AUTOSAR XML (schema 00044)
package /VehicleProject
  system System
    system mapping BMW_MPPNG
      data-mappings:
        sender-receiver-to-signal-mapping={data-element=Ambient_Light_level, system-signal=Ambient_Light_level}
        sender-receiver-to-signal-mapping={data-element=DayNightMode, system-signal=DayNightMode}
        sender-receiver-to-signal-mapping={data-element=Gear, system-signal=Gear}
        sender-receiver-to-signal-mapping={data-element=GearMode, system-signal=GearMode}
        sender-receiver-to-signal-mapping={data-element=GearRecommendation, system-signal=GearRecommendation}
        sender-receiver-to-signal-mapping={data-element=GearStatus, system-signal=GearStatus}
        sender-receiver-to-signal-mapping={data-element=Illumination_level, system-signal=Illumination_level}
        sender-receiver-to-signal-mapping={data-element=PowerMode, system-signal=PowerMode}
        sender-receiver-to-signal-mapping={data-element=TransportMode, system-signal=TransportMode}
        sender-receiver-to-signal-mapping={data-element=Warning, system-signal=Warning}
        sender-receiver-to-signal-mapping={data-element=Battery_Voltage, system-signal=Battery_Voltage}
        sender-receiver-to-signal-mapping={data-element=Debug1_Byte{0..7}, system-signal=Debug1_Byte{0..7}}
        sender-receiver-to-signal-mapping={data-element=Debug2_Byte{0..7}, system-signal=Debug2_Byte{0..7}}
        sender-receiver-to-signal-mapping={data-element=Debug3_Byte{0..7}, system-signal=Debug3_Byte{0..7}}
        sender-receiver-to-signal-mapping={data-element=Debug4_Byte{0..7}, system-signal=Debug4_Byte{0..7}}
        sender-receiver-to-signal-mapping={data-element=Debug5_Byte{0..7}, system-signal=Debug5_Byte{0..7}}
        sender-receiver-to-signal-mapping={data-element=FV_Tx, system-signal=FV_Tx}
        sender-receiver-to-signal-mapping={data-element=Illumination_PWM, system-signal=Illumination_PWM}
        sender-receiver-to-signal-mapping={data-element=MAC_Tx, system-signal=MAC_Tx}
        sender-receiver-to-signal-mapping={data-element=Odometer, system-signal=Odometer}
        sender-receiver-to-signal-mapping={data-element=SecureTxByte{0..3}, system-signal=SecureTxByte{0..3}}
        sender-receiver-to-signal-mapping={data-element=VehicleSpeedIC, system-signal=VehicleSpeedIC}
        sender-receiver-to-signal-group-mapping={data-element=SG_COM_HS, signal-group=SG_COM_HS, type-mapping=sender-rec-record-type-mapping=record-element-mappings=[{implementation-record-element=Alive_200, system-signal=Alive_200}, {implementation-record-element=Battery_Voltage, system-signal=Battery_Voltage}, {implementation-record-element=CRC_200, system-signal=CRC_200}]}
        sender-receiver-to-signal-group-mapping={data-element=PP_TX_SG_COM_HSSG_COM_HS.SG_COM_HS, signal-group=SG_COM_HS, type-mapping=sender-rec-record-type-mapping=record-element-mappings=[{implementation-record-element=Alive_200, system-signal=Alive_200}, {implementation-record-element=Battery_Voltage, system-signal=Battery_Voltage}, {implementation-record-element=CRC_200, system-signal=CRC_200}]}
        sender-receiver-to-signal-mapping={data-element=rp_SR_RxAmbient_Light_level.Ambient_Light_level, system-signal=Ambient_Light_level}
        sender-receiver-to-signal-mapping={data-element=CurrentStateIC, system-signal=CurrentStateIC}
        sender-receiver-to-signal-mapping={data-element=rp_SR_RxDayNightMode.DayNightMode, system-signal=DayNightMode}
        sender-receiver-to-signal-mapping={data-element=rp_SR_RxGear.Gear, system-signal=Gear}
        sender-receiver-to-signal-mapping={data-element=rp_SR_RxGearMode.GearMode, system-signal=GearMode}
        sender-receiver-to-signal-mapping={data-element=rp_SR_RxGearRecommendation.GearRecommendation, system-signal=GearRecommendation}
        sender-receiver-to-signal-mapping={data-element=rp_SR_RxGearStatus.GearStatus, system-signal=GearStatus}
        sender-receiver-to-signal-mapping={data-element=rp_SR_RxIllumination_level.Illumination_level, system-signal=Illumination_level}
        sender-receiver-to-signal-mapping={data-element=rp_SR_RxPowerMode.PowerMode, system-signal=PowerMode}
        sender-receiver-to-signal-mapping={data-element=rp_SR_RxTransportMode.TransportMode, system-signal=TransportMode}
        sender-receiver-to-signal-mapping={data-element=rp_SR_RxWarning.Warning, system-signal=Warning}
        sender-receiver-to-signal-mapping={data-element=pp_SR_TxDebug1_Byte{0..7}.Debug1_Byte{0..7}, system-signal=Debug1_Byte{0..7}}
        sender-receiver-to-signal-mapping={data-element=pp_SR_TxDebug2_Byte{0..7}.Debug2_Byte{0..7}, system-signal=Debug2_Byte{0..7}}
        sender-receiver-to-signal-mapping={data-element=pp_SR_TxDebug3_Byte{0..7}.Debug3_Byte{0..7}, system-signal=Debug3_Byte{0..7}}
        sender-receiver-to-signal-mapping={data-element=pp_SR_TxDebug4_Byte{0..7}.Debug4_Byte{0..7}, system-signal=Debug4_Byte{0..7}}
        sender-receiver-to-signal-mapping={data-element=pp_SR_TxDebug5_Byte{0..7}.Debug5_Byte{0..7}, system-signal=Debug5_Byte{0..7}}
        sender-receiver-to-signal-mapping={data-element=pp_SR_TxFV_Tx.FV_Tx, system-signal=FV_Tx}
        sender-receiver-to-signal-mapping={data-element=pp_SR_TxIllumination_PWM.Illumination_PWM, system-signal=Illumination_PWM}
        sender-receiver-to-signal-mapping={data-element=pp_SR_TxMAC_Tx.MAC_Tx, system-signal=MAC_Tx}
        sender-receiver-to-signal-mapping={data-element=pp_SR_TxOdometer.Odometer, system-signal=Odometer}
        sender-receiver-to-signal-mapping={data-element=pp_SR_TxSecureTxByte{0..3}.SecureTxByte{0..3}, system-signal=SecureTxByte{0..3}}
        sender-receiver-to-signal-mapping={data-element=pp_SR_TxVehicleSpeedIC.VehicleSpeedIC, system-signal=VehicleSpeedIC}
        sender-receiver-to-signal-mapping={data-element=EngineSpeed, system-signal=EngineSpeed}
        sender-receiver-to-signal-mapping={data-element=Turn_Indicator_Control, system-signal=Turn_Indicator_Control}
        sender-receiver-to-signal-mapping={data-element=rp_SR_RxEngineSpeed.EngineSpeed, system-signal=EngineSpeed}
        sender-receiver-to-signal-mapping={data-element=rp_SR_RxTurn_Indicator_Control.Turn_Indicator_Control, system-signal=Turn_Indicator_Control}
    root-software-compositions:
      root sw composition prototype SoftwareArchitecture: software-composition=E40_Platform_System
package /E40_Platform_System_SystemPackage/Compositions
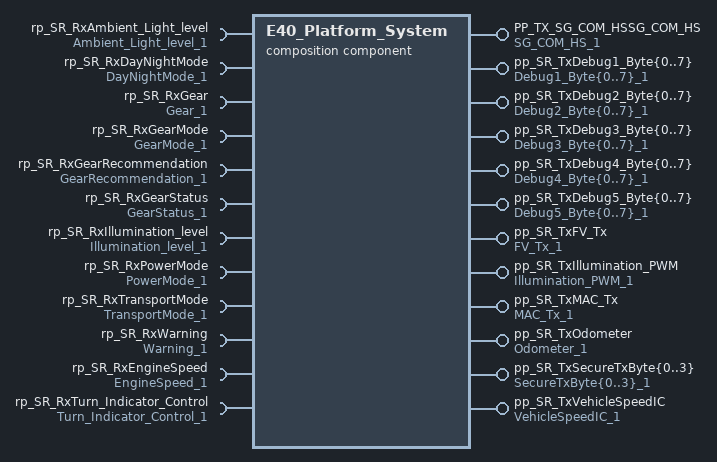
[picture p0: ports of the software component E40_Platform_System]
  composition sw component type E40_Platform_System
    provide port PP_TX_SG_COM_HSSG_COM_HS: nonqueued-sender-com-spec{data-element=SG_COM_HS, init-value=fields=[Alive_200:0, Battery_Voltage:0, CRC_200:0]}, provided-interface=SG_COM_HS_1
    10 x require port:
      rp_SR_RxAmbient_Light_level: nonqueued-receiver-com-spec{data-element=Ambient_Light_level, init-value=0}, required-interface=Ambient_Light_level_1
      rp_SR_RxDayNightMode: nonqueued-receiver-com-spec{data-element=DayNightMode, init-value=0}, required-interface=DayNightMode_1
      rp_SR_RxGear: nonqueued-receiver-com-spec{data-element=Gear, init-value=0}, required-interface=Gear_1
      rp_SR_RxGearMode: nonqueued-receiver-com-spec{data-element=GearMode, init-value=0}, required-interface=GearMode_1
      rp_SR_RxGearRecommendation: nonqueued-receiver-com-spec{data-element=GearRecommendation, init-value=0}, required-interface=GearRecommendation_1
      rp_SR_RxGearStatus: nonqueued-receiver-com-spec{data-element=GearStatus, init-value=0}, required-interface=GearStatus_1
      rp_SR_RxIllumination_level: nonqueued-receiver-com-spec{data-element=Illumination_level, init-value=0}, required-interface=Illumination_level_1
      rp_SR_RxPowerMode: nonqueued-receiver-com-spec{data-element=PowerMode, init-value=0}, required-interface=PowerMode_1
      rp_SR_RxTransportMode: nonqueued-receiver-com-spec{data-element=TransportMode, init-value=0}, required-interface=TransportMode_1
      rp_SR_RxWarning: nonqueued-receiver-com-spec{data-element=Warning, init-value=0}, required-interface=Warning_1
    49 x provide port:
      pp_SR_TxDebug1_Byte{0..7}: nonqueued-sender-com-spec{data-element=Debug1_Byte{0..7}, init-value=0}, provided-interface=Debug1_Byte{0..7}_1
      pp_SR_TxDebug2_Byte{0..7}: nonqueued-sender-com-spec{data-element=Debug2_Byte{0..7}, init-value=0}, provided-interface=Debug2_Byte{0..7}_1
      pp_SR_TxDebug3_Byte{0..7}: nonqueued-sender-com-spec{data-element=Debug3_Byte{0..7}, init-value=0}, provided-interface=Debug3_Byte{0..7}_1
      pp_SR_TxDebug4_Byte{0..7}: nonqueued-sender-com-spec{data-element=Debug4_Byte{0..7}, init-value=0}, provided-interface=Debug4_Byte{0..7}_1
      pp_SR_TxDebug5_Byte{0..7}: nonqueued-sender-com-spec{data-element=Debug5_Byte{0..7}, init-value=0}, provided-interface=Debug5_Byte{0..7}_1
      pp_SR_TxFV_Tx: nonqueued-sender-com-spec{data-element=FV_Tx, init-value=0}, provided-interface=FV_Tx_1
      pp_SR_TxIllumination_PWM: nonqueued-sender-com-spec{data-element=Illumination_PWM, init-value=0}, provided-interface=Illumination_PWM_1
      pp_SR_TxMAC_Tx: nonqueued-sender-com-spec{data-element=MAC_Tx, init-value=0}, provided-interface=MAC_Tx_1
      pp_SR_TxOdometer: nonqueued-sender-com-spec{data-element=Odometer, init-value=0}, provided-interface=Odometer_1
      pp_SR_TxSecureTxByte{0..3}: nonqueued-sender-com-spec{data-element=SecureTxByte{0..3}, init-value=0}, provided-interface=SecureTxByte{0..3}_1
      pp_SR_TxVehicleSpeedIC: nonqueued-sender-com-spec{data-element=VehicleSpeedIC, init-value=0}, provided-interface=VehicleSpeedIC_1
    require port rp_SR_RxEngineSpeed: nonqueued-receiver-com-spec{data-element=EngineSpeed, init-value=0}, required-interface=EngineSpeed_1
    require port rp_SR_RxTurn_Indicator_Control: nonqueued-receiver-com-spec{data-element=Turn_Indicator_Control, init-value=0}, required-interface=Turn_Indicator_Control_1
    74 x component:
      Test_Comp: type=Test_Comp
      NvMExt: type=NvMExt
      EcuMExt: type=EcuMExt
      TmExt: type=TmExt
      IoHwAb: type=IoHwAb
      EcuAppM: type=EcuAppM
      MemAbstractMdl: type=MemAbstractMdl
      DmnMgr: type=DmnMgr
      SciDrv: type=SciDrv
      UclProxyCdd: type=UclProxyCdd
      CCDD_EcuPowerM: type=CCDD_EcuPowerM
      Dlt: type=Dlt
      DltExt: type=DltExt
      CDisplayCdd: type=CDisplayCdd
      CBacklightCdd: type=CBacklightCdd
      RtcCdd: type=RtcCdd
      DcmExt: type=DcmExt
      DemExt: type=DemExt
      CMeetCdd: type=CMeetCdd
      GdtCdd: type=GdtCdd
      WdgM: type=WdgM
      DcmApp: type=DcmApp
      DemApp: type=DemApp
      SafeBsw: type=SafeBsw
      CPmicCdd: type=CPmicCdd
      CIoExp: type=CIoExp
      CComAbsCtrl: type=CComAbsCtrl
      CComAbsMdl: type=CComAbsMdl
      CCtrl_Telltale: type=CCtrl_Telltale
      Ctrl_Dim: type=Ctrl_Dim
      Ctrl_warning: type=Ctrl_warning
      Ctrl_WSS: type=Ctrl_WSS
      CView_Telltale: type=CView_Telltale
      CWarnMsg_Core_Observer: type=CWarnMsg_Core_Observer
      FastGaugeAdapter: type=FastGaugeAdapter
      Mdl_Airbag: type=Mdl_Airbag
      Mdl_Dim: type=Mdl_Dim
      Mdl_Gear: type=Mdl_Gear
      Mdl_Linear_Interpolation: type=Mdl_Linear_Interpolation
      Mdl_SafetyAdapter: type=Mdl_SafetyAdapter
      Mdl_Speed: type=Mdl_Speed
      Mdl_Tacho: type=Mdl_Tacho
      Mdl_TurnHazard: type=Mdl_TurnHazard
      Mdl_wFuelLidOpen: type=Mdl_wFuelLidOpen
      Mdl_wAirbag: type=Mdl_wAirbag
      View_Speed: type=View_Speed
      SlowGaugeAdapter: type=SlowGaugeAdapter
      WarnMsg_Core_TmrSupport: type=WarnMsg_Core_TmrSupport
      ComMExt: type=ComMExt
      CorTst: type=CorTst
      FlsTst: type=FlsTst
      NvMExtSf: type=NvMExtSf
      RamTst: type=RamTst
      SysTst: type=SysTst
      MemAbstractStub: type=MemAbstractStub
      NvBlockSwComponentType: type=NvBlockSwComponentType
      CUpdateCdd: type=CUpdateCdd
      SafeNvM: type=SafeNvM
      MemAbstract_Stub_Safe: type=MemAbstract_Stub_Safe
      ComCallout: type=ComCallout
      CFltM: type=CFltM
      CFltMExt: type=CFltMExt
      CCDD_BswFit: type=CCDD_BswFit
      CCDD_FitManager: type=CCDD_FitManager
      CCDD_McuFit: type=CCDD_McuFit
      Ctrl_Illumination: type=Ctrl_Illumination
      View_Illumination: type=View_Illumination
      CComAbsMdl_stubs: type=CComAbsMdl_stubs
      CComAbsMdlSafe: type=CComAbsMdlSafe
      TrustecSWC: type=TrustecSWC
      CRstM: type=CRstM
      CSigCdd: type=CSigCdd
      CSwcDispMonSf: type=CSwcDispMonSf
      CCDD_EcuBatteryM: type=CCDD_EcuBatteryM
    connect IoHwAb.ppIoHwAb_Din -> CCDD_EcuPowerM.rpIoHwAb_Din
    connect IoHwAb.ppIoHwAb_DOut -> CCDD_EcuPowerM.rpIoHwAb_DOut
    connect IoHwAb.ppIoHwAb_PWM -> CCDD_EcuPowerM.rpIoHwAb_PWM
    connect IoHwAb.ppIoHwAb_ADC -> CCDD_EcuPowerM.rpIoHwAb_ADC
    connect MemAbstractMdl.pp_CS_MemAbsGet -> DltExt.rp_CS_MemAbsGet
    connect MemAbstractMdl.pp_CS_MemAbsSet -> DltExt.rp_CS_MemAbsSet
    connect MemAbstractMdl.pp_CS_MemAbs_NvMWriteStatus -> DltExt.rp_CS_MemAbs_NvMWriteStatus
    connect DmnMgr.ppCS_UclSystemCallbacks -> UclProxyCdd.rCS_UclSystemCallbacks
    connect DmnMgr.pSR_HealthDumpGetHdr -> UclProxyCdd.rSR_HealthDumpGetHdr
    connect DmnMgr.pSR_HealthDumpGetData -> UclProxyCdd.rSR_HealthDumpGetData
    connect DmnMgr.pSR_PowerSystemStateReqChange -> UclProxyCdd.rSR_PowerSystemStateReqChange
    connect UclProxyCdd.pSR_HealthDomainFatalError -> DmnMgr.rSR_HealthDomainFatalError
    connect UclProxyCdd.pSR_HealthDomainHeartbeat -> DmnMgr.rSR_HealthDomainHeartbeat
    connect UclProxyCdd.pSR_HealthDumpData -> DmnMgr.rSR_HealthDumpData
    connect UclProxyCdd.pSR_HealthDumpHdrInfo -> DmnMgr.rSR_HealthDumpHdrInfo
    connect UclProxyCdd.pSR_PowerExtendShutdownTime -> DmnMgr.rSR_PowerExtendShutdownTime
    connect UclProxyCdd.pSR_PowerKeepSystemAwake -> DmnMgr.rSR_PowerKeepSystemAwake
    connect UclProxyCdd.pSR_PowerSystemState -> DmnMgr.rSR_PowerSystemState
    connect UclProxyCdd.ppCS_UclInitShutdown -> DmnMgr.rpCS_UclInitShutdown
    connect DmnMgr.ppSR_DmnInfo -> DmnMgr.rpSR_DmnInfo
    connect DmnMgr.pp_CmpLibCmd_CDmnMgr -> EcuAppM.rp_CmpLibCmd_rp_CmpLibCmd_CDmnMgr
    connect UclProxyCdd.pp_CmpLibCmd_CUclProxyCdd -> EcuAppM.rp_CmpLibCmd_rp_CmpLibCmd_CUclProxyCdd
    connect EcuAppM.ppCS_EcuAppM -> EcuMExt.rpCS_EcuAppM
    connect NvBlockSwComponentType.BsShare_VisMeet_Element -> MemAbstractStub
    connect NvBlockSwComponentType.BsDiag_Dtc_Element -> MemAbstractStub
    connect NvBlockSwComponentType.BsRt_OilGauge_Element -> MemAbstractStub
    connect NvBlockSwComponentType.BsConst_ServiceReminder_Element -> MemAbstractStub
    connect NvBlockSwComponentType.BsRt_TachoGauge_Element -> MemAbstractStub
    connect NvBlockSwComponentType.BsConst_EngOffTimer_Element -> MemAbstractStub
    connect NvBlockSwComponentType.BsShare_ProductSerialNumber -> MemAbstractStub
    connect NvBlockSwComponentType.BsConst_OilGauge_Element -> MemAbstractStub
    connect NvBlockSwComponentType.BsRt_Odometer_Element -> MemAbstractStub
    connect NvBlockSwComponentType -> MemAbstractStub
    connect NvBlockSwComponentType -> MemAbstractStub
    connect NvBlockSwComponentType.BsReten_Audio_Element -> MemAbstractStub
    connect NvBlockSwComponentType.BsRt_TripComputer_Element -> MemAbstractStub
    connect NvBlockSwComponentType.BsReten_Power_Element -> MemAbstractStub
    connect NvBlockSwComponentType -> MemAbstractStub
    connect NvBlockSwComponentType.BsShare_SwUpdFotadecrypt_Element -> MemAbstractStub
    connect NvBlockSwComponentType.BsConst_Communication_Element -> MemAbstractStub
    connect NvBlockSwComponentType.BsRt_TempGauge_Element -> MemAbstractStub
    connect NvBlockSwComponentType.BsRt_SpeedoGauge_Element -> MemAbstractStub
    connect NvBlockSwComponentType.BsShare_SwUpdReflash_Element -> MemAbstractStub
    connect NvBlockSwComponentType -> MemAbstractStub
    connect NvBlockSwComponentType.BsShare_SwUpdFotaStatus_Element -> MemAbstractStub
    connect NvBlockSwComponentType -> MemAbstractStub
    connect NvBlockSwComponentType.BsShare_EcuPartNumber_Element -> MemAbstractStub
    connect NvBlockSwComponentType.BsConst_PowerGauge_Element -> MemAbstractStub
    connect NvBlockSwComponentType.BsConst_RealTimeClock_Element -> MemAbstractStub
    connect NvBlockSwComponentType.BsReten_Communication_Element -> MemAbstractStub
    connect NvBlockSwComponentType -> MemAbstractStub
    connect NvBlockSwComponentType.BsShare_PCBSerialNumber -> MemAbstractStub
    connect NvBlockSwComponentType.RefCys_Certicificate_Element -> MemAbstractStub
    connect NvBlockSwComponentType.BsReten_Illumination_Element -> MemAbstractStub
    connect NvBlockSwComponentType.BsReten_Tripcomputer_Element -> MemAbstractStub
    connect NvBlockSwComponentType.BsConst_FuelGauge_Element -> MemAbstractStub
    connect NvBlockSwComponentType.BsRt_PowerGauge_Element -> MemAbstractStub
    connect NvBlockSwComponentType.BsShare_HWModification -> MemAbstractStub
    connect NvBlockSwComponentType.BsShare_AssemblyManufacturingDate -> MemAbstractStub
    connect NvBlockSwComponentType -> MemAbstractStub
    connect NvBlockSwComponentType.RefCys_Certicificate1_Element -> MemAbstractStub
    connect NvBlockSwComponentType.BsRt_FuelGauge_Element -> MemAbstractStub
    connect NvBlockSwComponentType.BsReten_Odometer_Element -> MemAbstractStub
    connect NvBlockSwComponentType.BsShare_SMTPlantNumber -> MemAbstractStub
    connect NvBlockSwComponentType.BsConst_SpeedoGauge_Element -> MemAbstractStub
    connect NvBlockSwComponentType.BsConst_TripComputer_Element -> MemAbstractStub
    connect NvBlockSwComponentType.BsShare_VisMeet_EOLEntry_Element -> MemAbstractStub
    connect NvBlockSwComponentType.BsReten_Display_Element -> MemAbstractStub
    connect NvBlockSwComponentType.BsRt_CusDlt_Element -> MemAbstractStub
    connect NvBlockSwComponentType.BsRt_Personalization_Element -> MemAbstractStub
    connect NvBlockSwComponentType.BsRt_Warning_Element -> MemAbstractStub
    connect NvBlockSwComponentType.BsConst_TachoGauge_Element -> MemAbstractStub
    connect NvBlockSwComponentType.BsShare_VisteonPCBPartNumber -> MemAbstractStub
    connect NvBlockSwComponentType.BsShare_AssemblyPlantNumber -> MemAbstractStub
    connect NvBlockSwComponentType.BsDiag_ErrorRecord_Element -> MemAbstractStub
    connect NvBlockSwComponentType.BsCys_Certicificate_Element -> MemAbstractStub
    connect NvBlockSwComponentType.BsReten_Warning_Element -> MemAbstractStub
    connect NvBlockSwComponentType.BsRt_Illumination_Element -> MemAbstractStub
    connect NvBlockSwComponentType -> MemAbstractStub
    connect NvBlockSwComponentType.BsShare_SwUpdFotaFinPrint_Element -> MemAbstractStub
    connect NvBlockSwComponentType.BsShare_VehicleConfig_Element -> MemAbstractStub
    connect NvBlockSwComponentType.BsReten_RealTimeClock_Element -> MemAbstractStub
    connect NvBlockSwComponentType.BsRt_RealTimeClock_Element -> MemAbstractStub
    connect NvBlockSwComponentType.BsReten_Gauges_Element -> MemAbstractStub
    connect NvBlockSwComponentType.BsConst_TempGauge_Element -> MemAbstractStub
    connect NvBlockSwComponentType.BsConst_Warning_Element -> MemAbstractStub
    connect NvBlockSwComponentType.BsConst_Audio_Element -> MemAbstractStub
    connect NvBlockSwComponentType.BsConst_Power_Element -> MemAbstractStub
    connect NvBlockSwComponentType.BsShare_VisteonPartNumber -> MemAbstractStub
    connect NvBlockSwComponentType.BsShare_SMTManufacturingDate -> MemAbstractStub
    connect NvBlockSwComponentType.BsShare_SwUpdFotaMode_Element -> MemAbstractStub
    connect NvBlockSwComponentType.BsReten_Personalization_Element -> MemAbstractStub
    connect NvBlockSwComponentType.BsRt_TachoGauge_Element -> MemAbstractStub
    connect NvBlockSwComponentType.BsRt_PowerGauge_Element -> MemAbstractStub
    connect NvBlockSwComponentType.BsReten_Audio_Element -> MemAbstractStub
    connect NvBlockSwComponentType.BsConst_TachoGauge_Element -> MemAbstractStub
    connect NvBlockSwComponentType.RefCys_Certicificate1_Element -> MemAbstractStub
    connect NvBlockSwComponentType.BsConst_PowerGauge_Element -> MemAbstractStub
    connect NvBlockSwComponentType.BsRt_Odometer_Element -> MemAbstractStub
    connect NvBlockSwComponentType.BsConst_TempGauge_Element -> MemAbstractStub
    connect NvBlockSwComponentType.BsConst_Audio_Element -> MemAbstractStub
    connect NvBlockSwComponentType.BsConst_Communication_Element -> MemAbstractStub
    connect NvBlockSwComponentType.BsShare_VehicleConfig_Element -> MemAbstractStub
    connect NvBlockSwComponentType.BsConst_EngOffTimer_Element -> MemAbstractStub
    connect NvBlockSwComponentType.BsConst_FuelGauge_Element -> MemAbstractStub
    connect NvBlockSwComponentType.BsCys_Certicificate_Element -> MemAbstractStub
    connect NvBlockSwComponentType.BsReten_RealTimeClock_Element -> MemAbstractStub
    connect NvBlockSwComponentType.BsShare_PCBSerialNumber -> MemAbstractStub
    connect NvBlockSwComponentType.BsRt_Illumination_Element -> MemAbstractStub
    connect NvBlockSwComponentType.BsReten_Illumination_Element -> MemAbstractStub
    connect NvBlockSwComponentType.BsReten_Display_Element -> MemAbstractStub
    connect NvBlockSwComponentType.BsShare_AssemblyPlantNumber -> MemAbstractStub
    connect NvBlockSwComponentType.BsConst_SpeedoGauge_Element -> MemAbstractStub
    connect NvBlockSwComponentType.BsReten_Gauges_Element -> MemAbstractStub
    connect NvBlockSwComponentType.BsConst_OilGauge_Element -> MemAbstractStub
    connect NvBlockSwComponentType.BsConst_ServiceReminder_Element -> MemAbstractStub
    connect NvBlockSwComponentType.BsRt_SpeedoGauge_Element -> MemAbstractStub
    connect NvBlockSwComponentType.BsReten_Warning_Element -> MemAbstractStub
    connect NvBlockSwComponentType.BsConst_Power_Element -> MemAbstractStub
    connect NvBlockSwComponentType.BsShare_SwUpdFotaStatus_Element -> MemAbstractStub
    connect NvBlockSwComponentType.BsShare_SwUpdFotaMode_Element -> MemAbstractStub
    connect NvBlockSwComponentType.BsDiag_Dtc_Element -> MemAbstractStub
    connect NvBlockSwComponentType.BsShare_VisMeet_Element -> MemAbstractStub
    connect NvBlockSwComponentType.RefCys_Certicificate_Element -> MemAbstractStub
    connect NvBlockSwComponentType.BsShare_SwUpdFotadecrypt_Element -> MemAbstractStub
    connect NvBlockSwComponentType.BsConst_RealTimeClock_Element -> MemAbstractStub
    connect NvBlockSwComponentType.BsRt_FuelGauge_Element -> MemAbstractStub
    connect NvBlockSwComponentType.BsConst_TripComputer_Element -> MemAbstractStub
    connect NvBlockSwComponentType.BsShare_AssemblyManufacturingDate -> MemAbstractStub
    connect NvBlockSwComponentType.BsShare_SwUpdReflash_Element -> MemAbstractStub
    connect NvBlockSwComponentType.BsShare_HWModification -> MemAbstractStub
    connect NvBlockSwComponentType -> MemAbstractStub
    connect NvBlockSwComponentType.BsRt_RealTimeClock_Element -> MemAbstractStub
    connect NvBlockSwComponentType.BsDiag_ErrorRecord_Element -> MemAbstractStub
    connect NvBlockSwComponentType.BsShare_SMTPlantNumber -> MemAbstractStub
    connect NvBlockSwComponentType.BsReten_Communication_Element -> MemAbstractStub
    connect NvBlockSwComponentType.BsShare_ProductSerialNumber -> MemAbstractStub
    connect NvBlockSwComponentType.BsShare_EcuPartNumber_Element -> MemAbstractStub
    connect NvBlockSwComponentType.BsShare_SMTManufacturingDate -> MemAbstractStub
    connect NvBlockSwComponentType.BsReten_Power_Element -> MemAbstractStub
    connect NvBlockSwComponentType.BsReten_Personalization_Element -> MemAbstractStub
    connect NvBlockSwComponentType.BsShare_VisteonPCBPartNumber -> MemAbstractStub
    connect NvBlockSwComponentType.BsShare_VisMeet_EOLEntry_Element -> MemAbstractStub
    connect NvBlockSwComponentType.BsReten_Tripcomputer_Element -> MemAbstractStub
    connect NvBlockSwComponentType.BsRt_OilGauge_Element -> MemAbstractStub
    connect NvBlockSwComponentType.BsShare_VisteonPartNumber -> MemAbstractStub
    connect NvBlockSwComponentType.BsRt_TempGauge_Element -> MemAbstractStub
    connect NvBlockSwComponentType.BsReten_Odometer_Element -> MemAbstractStub
    connect NvBlockSwComponentType.BsRt_Personalization_Element -> MemAbstractStub
    connect NvBlockSwComponentType.BsRt_TripComputer_Element -> MemAbstractStub
    connect NvBlockSwComponentType.BsRt_Warning_Element -> MemAbstractStub
    connect NvBlockSwComponentType.BsConst_Warning_Element -> MemAbstractStub
    connect NvBlockSwComponentType.BsRt_CusDlt_Element -> MemAbstractStub
    connect NvBlockSwComponentType.BsShare_SwUpdFotaFinPrint_Element -> MemAbstractStub
    connect NvBlockSwComponentType.BsReten_Tripcomputer_Element -> MemAbstractStub
    connect NvBlockSwComponentType.BsConst_Derating_Backlight_Disable_SafeCopy1 -> MemAbstractStub
    connect NvBlockSwComponentType.BsConst_TripComputer_Element -> MemAbstractStub
    connect NvBlockSwComponentType.BsReten_Audio_Element -> MemAbstractStub
    connect NvBlockSwComponentType.BsConst_PWM_boost_bypass_duty_SafeCopy1 -> MemAbstractStub
    connect NvBlockSwComponentType.BsShare_VisMeet_Element -> MemAbstractStub
    connect NvBlockSwComponentType.BsShare_VisteonPartNumber -> MemAbstractStub
    connect NvBlockSwComponentType.BsShare_SwUpdFotadecrypt_Element -> MemAbstractStub
    connect NvBlockSwComponentType.BsRt_Warning_Element -> MemAbstractStub
    connect NvBlockSwComponentType -> MemAbstractStub
    connect NvBlockSwComponentType.BsShare_AssemblyPlantNumber -> MemAbstractStub
    connect NvBlockSwComponentType.BsConst_PCB_Temperature_Sensor_Conv -> MemAbstractStub
    connect NvBlockSwComponentType.BsConst_PWM_boost_bypass_duty_SafeCopy2 -> MemAbstractStub
    connect NvBlockSwComponentType.BsShare_SwUpdFotaStatus_Element -> MemAbstractStub
    connect NvBlockSwComponentType.BsConst_Temp_Threshold_Hysteresis_Derating_SafeCopy2 -> MemAbstractStub
    connect NvBlockSwComponentType.BsReten_Illumination_Element -> MemAbstractStub
    connect NvBlockSwComponentType.BsShare_AssemblyManufacturingDate -> MemAbstractStub
    connect NvBlockSwComponentType.BsRt_RealTimeClock_Element -> MemAbstractStub
    connect NvBlockSwComponentType.BsConst_Temp_Threshold_Hysteresis_Derating_SafeCopy1 -> MemAbstractStub
    connect NvBlockSwComponentType.BsConst_PWM_boost_bypass_duty -> MemAbstractStub
    connect NvBlockSwComponentType.BsConst_Lookup_Curve_HotSpot_Coef_Y_SafeCopy2 -> MemAbstractStub
    connect NvBlockSwComponentType.BsShare_SMTManufacturingDate -> MemAbstractStub
    connect NvBlockSwComponentType.BsConst_Compensation_Line_Slope_m -> MemAbstractStub
    connect NvBlockSwComponentType.BsConst_Temperature_Sensor_Conv_SafeCopy2 -> MemAbstractStub
    connect NvBlockSwComponentType.BsConst_Compensation_Line_Slope_m_SafeCopy1 -> MemAbstractStub
    connect NvBlockSwComponentType.BsConst_Compensation_Line_Shift_b_SafeCopy1 -> MemAbstractStub
    connect NvBlockSwComponentType -> MemAbstractStub
    connect NvBlockSwComponentType.BsRt_OilGauge_Element -> MemAbstractStub
    connect NvBlockSwComponentType.BsShare_SwUpdReflash_Element -> MemAbstractStub
    connect NvBlockSwComponentType.BsConst_Temp_Threshold_Hysteresis_Derating -> MemAbstractStub
    connect NvBlockSwComponentType.BsReten_Power_Element -> MemAbstractStub
    connect NvBlockSwComponentType.BsConst_Audio_Element -> MemAbstractStub
    connect NvBlockSwComponentType.BsShare_VisteonPCBPartNumber -> MemAbstractStub
    connect NvBlockSwComponentType.BsReten_Communication_Element -> MemAbstractStub
    connect NvBlockSwComponentType.BsConst_Display_Illum_Max_Level_SafeCopy1 -> MemAbstractStub
    connect NvBlockSwComponentType.BsConst_RealTimeClock_Element -> MemAbstractStub
    connect NvBlockSwComponentType.BsReten_Warning_Element -> MemAbstractStub
    connect NvBlockSwComponentType.BsRt_SpeedoGauge_Element -> MemAbstractStub
    connect NvBlockSwComponentType.BsDiag_Dtc_Element -> MemAbstractStub
    connect NvBlockSwComponentType.BsReten_Gauges_Element -> MemAbstractStub
    connect NvBlockSwComponentType.BsConst_Display_Illum_Max_Level -> MemAbstractStub
    connect NvBlockSwComponentType.BsRt_Odometer_Element -> MemAbstractStub
    connect NvBlockSwComponentType.BsRt_FuelGauge_Element -> MemAbstractStub
    connect NvBlockSwComponentType.BsRt_Illumination_Element -> MemAbstractStub
    connect NvBlockSwComponentType -> MemAbstractStub
    connect NvBlockSwComponentType.RefCys_Certicificate1_Element -> MemAbstractStub
    connect NvBlockSwComponentType.BsConst_PCB_Temperature_Sensor_Conv_SafeCopy2 -> MemAbstractStub
    connect NvBlockSwComponentType.BsConst_Temperature_Sensor_Conv_SafeCopy1 -> MemAbstractStub
    connect NvBlockSwComponentType.BsConst_Lookup_Curve_HotSpot_Coef_X -> MemAbstractStub
    connect NvBlockSwComponentType.BsConst_Lookup_Curve_HotSpot_Coef_Y -> MemAbstractStub
    connect NvBlockSwComponentType.BsShare_HWModification -> MemAbstractStub
    connect NvBlockSwComponentType.BsConst_Compensation_Line_Slope_m_SafeCopy2 -> MemAbstractStub
    connect NvBlockSwComponentType.BsConst_Communication_Element -> MemAbstractStub
    connect NvBlockSwComponentType.BsRt_TempGauge_Element -> MemAbstractStub
    connect NvBlockSwComponentType.BsRt_CusDlt_Element -> MemAbstractStub
    connect NvBlockSwComponentType.BsConst_BsConst_Illumination_ReservedByte_SafeCopy1 -> MemAbstractStub
    connect NvBlockSwComponentType.BsConst_BsConst_Illumination_ReservedByte -> MemAbstractStub
    connect NvBlockSwComponentType.BsConst_EngOffTimer_Element -> MemAbstractStub
    connect NvBlockSwComponentType.BsConst_PCB_Temperature_Sensor_Conv_SafeCopy1 -> MemAbstractStub
    connect NvBlockSwComponentType.BsRt_PowerGauge_Element -> MemAbstractStub
    connect NvBlockSwComponentType.BsConst_Warning_Element -> MemAbstractStub
    connect NvBlockSwComponentType.BsConst_TachoGauge_Element -> MemAbstractStub
    connect NvBlockSwComponentType.BsConst_ServiceReminder_Element -> MemAbstractStub
    connect NvBlockSwComponentType.BsConst_Lookup_Curve_HotSpot_Coef_X_SafeCopy1 -> MemAbstractStub
    connect NvBlockSwComponentType.BsDiag_ErrorRecord_Element -> MemAbstractStub
    connect NvBlockSwComponentType.BsConst_Compensation_Line_Shift_b -> MemAbstractStub
    connect NvBlockSwComponentType.BsConst_SpeedoGauge_Element -> MemAbstractStub
    connect NvBlockSwComponentType.BsShare_EcuPartNumber_Element -> MemAbstractStub
    connect NvBlockSwComponentType.BsShare_SwUpdFotaMode_Element -> MemAbstractStub
    connect NvBlockSwComponentType.BsReten_Display_Element -> MemAbstractStub
    connect NvBlockSwComponentType.BsConst_OilGauge_Element -> MemAbstractStub
    connect NvBlockSwComponentType.BsConst_Power_Element -> MemAbstractStub
    connect NvBlockSwComponentType.BsShare_ProductSerialNumber -> MemAbstractStub
    connect NvBlockSwComponentType.BsShare_PCBSerialNumber -> MemAbstractStub
    connect NvBlockSwComponentType.BsRt_TripComputer_Element -> MemAbstractStub
    connect NvBlockSwComponentType.BsReten_Odometer_Element -> MemAbstractStub
    connect NvBlockSwComponentType.BsConst_Display_Illum_Max_Level_SafeCopy2 -> MemAbstractStub
    connect NvBlockSwComponentType.BsRt_Personalization_Element -> MemAbstractStub
    connect NvBlockSwComponentType.BsReten_RealTimeClock_Element -> MemAbstractStub
    connect NvBlockSwComponentType.BsConst_FuelGauge_Element -> MemAbstractStub
    connect NvBlockSwComponentType.RefCys_Certicificate_Element -> MemAbstractStub
    connect NvBlockSwComponentType.BsConst_PowerGauge_Element -> MemAbstractStub
    connect NvBlockSwComponentType.BsShare_SwUpdFotaFinPrint_Element -> MemAbstractStub
    connect NvBlockSwComponentType.BsCys_Certicificate_Element -> MemAbstractStub
    connect NvBlockSwComponentType.BsConst_Lookup_Curve_HotSpot_Coef_X_SafeCopy2 -> MemAbstractStub
    connect NvBlockSwComponentType.BsShare_SMTPlantNumber -> MemAbstractStub
    connect NvBlockSwComponentType -> MemAbstractStub
    connect NvBlockSwComponentType.BsRt_TachoGauge_Element -> MemAbstractStub
    connect NvBlockSwComponentType.BsConst_Lookup_Curve_HotSpot_Coef_Y_SafeCopy1 -> MemAbstractStub
    connect NvBlockSwComponentType.BsReten_Personalization_Element -> MemAbstractStub
    connect NvBlockSwComponentType.BsConst_TempGauge_Element -> MemAbstractStub
    connect NvBlockSwComponentType.BsConst_Compensation_Line_Shift_b_SafeCopy2 -> MemAbstractStub
    connect NvBlockSwComponentType.BsShare_VisMeet_EOLEntry_Element -> MemAbstractStub
    connect NvBlockSwComponentType.BsConst_Derating_Backlight_Disable_SafeCopy2 -> MemAbstractStub
    connect NvBlockSwComponentType.BsConst_Temperature_Sensor_Conv -> MemAbstractStub
    connect NvBlockSwComponentType.BsConst_Derating_Backlight_Disable -> MemAbstractStub
    connect NvBlockSwComponentType.BsShare_VehicleConfig_Element -> MemAbstractStub
    connect NvBlockSwComponentType.BsConst_BsConst_Illumination_ReservedByte_SafeCopy2 -> MemAbstractStub
    connect MemAbstract_Stub_Safe.BsConst_Lookup_Curve_HotSpot_Coef_Y -> SafeNvM
    connect MemAbstract_Stub_Safe.BsConst_Derating_Backlight_Disable -> SafeNvM
    connect MemAbstract_Stub_Safe.BsConst_Compensation_Line_Slope_m -> SafeNvM
    connect MemAbstract_Stub_Safe.BsConst_BsConst_Illumination_ReservedByte -> SafeNvM
    connect MemAbstract_Stub_Safe.BsConst_PWM_boost_bypass_duty -> SafeNvM
    connect MemAbstract_Stub_Safe.BsConst_Temperature_Sensor_Conv -> SafeNvM
    connect MemAbstract_Stub_Safe.BsConst_Lookup_Curve_HotSpot_Coef_X -> SafeNvM
    connect MemAbstract_Stub_Safe.BsConst_PCB_Temperature_Sensor_Conv -> SafeNvM
    connect MemAbstract_Stub_Safe.BsConst_Temp_Threshold_Hysteresis_Derating -> SafeNvM
    connect MemAbstract_Stub_Safe.BsConst_Compensation_Line_Shift_b -> SafeNvM
    connect MemAbstract_Stub_Safe.BsConst_Display_Illum_Max_Level_Safe -> SafeNvM
    connect MemAbstract_Stub_Safe.BsConst_PWM_boost_bypass_duty -> SafeNvM
    connect MemAbstract_Stub_Safe.BsConst_Compensation_Line_Slope_m -> SafeNvM
    connect MemAbstract_Stub_Safe.BsConst_Lookup_Curve_HotSpot_Coef_X -> SafeNvM
    connect MemAbstract_Stub_Safe.BsConst_PCB_Temperature_Sensor_Conv -> SafeNvM
    connect MemAbstract_Stub_Safe.BsConst_Display_Illum_Max_Level_Safe -> SafeNvM
    connect MemAbstract_Stub_Safe.BsConst_Derating_Backlight_Disable -> SafeNvM
    connect MemAbstract_Stub_Safe.BsConst_Temperature_Sensor_Conv -> SafeNvM
    connect MemAbstract_Stub_Safe.BsConst_BsConst_Illumination_ReservedByte -> SafeNvM
    connect MemAbstract_Stub_Safe.BsConst_Temp_Threshold_Hysteresis_Derating -> SafeNvM
    connect MemAbstract_Stub_Safe.BsConst_Compensation_Line_Shift_b -> SafeNvM
    connect MemAbstract_Stub_Safe.BsConst_Lookup_Curve_HotSpot_Coef_Y -> SafeNvM
    connect MemAbstract_Stub_Safe.BsConst_Compensation_Line_Slope_m -> SafeNvM
    connect MemAbstract_Stub_Safe.BsConst_Derating_Backlight_Disable -> SafeNvM
    connect MemAbstract_Stub_Safe.BsConst_Temperature_Sensor_Conv -> SafeNvM
    connect MemAbstract_Stub_Safe.BsConst_BsConst_Illumination_ReservedByte -> SafeNvM
    connect MemAbstract_Stub_Safe.BsConst_Temp_Threshold_Hysteresis_Derating -> SafeNvM
    connect MemAbstract_Stub_Safe.BsConst_Lookup_Curve_HotSpot_Coef_Y -> SafeNvM
    connect MemAbstract_Stub_Safe.BsConst_PWM_boost_bypass_duty -> SafeNvM
    connect MemAbstract_Stub_Safe.BsConst_Lookup_Curve_HotSpot_Coef_X -> SafeNvM
    connect MemAbstract_Stub_Safe.BsConst_Compensation_Line_Shift_b -> SafeNvM
    connect MemAbstract_Stub_Safe.BsConst_PCB_Temperature_Sensor_Conv -> SafeNvM
    connect MemAbstract_Stub_Safe.BsConst_Display_Illum_Max_Level_Safe -> SafeNvM
    connect MemAbstract_Stub_Safe.BsConst_Derating_Backlight_Disable -> SafeNvM
    connect MemAbstract_Stub_Safe.BsConst_Compensation_Line_Slope_m -> SafeNvM
    connect MemAbstract_Stub_Safe.BsConst_Lookup_Curve_HotSpot_Coef_Y -> SafeNvM
    connect MemAbstract_Stub_Safe.BsConst_Temperature_Sensor_Conv -> SafeNvM
    connect MemAbstract_Stub_Safe.BsConst_Compensation_Line_Shift_b -> SafeNvM
    connect MemAbstract_Stub_Safe.BsConst_Temp_Threshold_Hysteresis_Derating -> SafeNvM
    connect MemAbstract_Stub_Safe.BsConst_BsConst_Illumination_ReservedByte -> SafeNvM
    connect MemAbstract_Stub_Safe.BsConst_Display_Illum_Max_Level_Safe -> SafeNvM
    connect MemAbstract_Stub_Safe.BsConst_Lookup_Curve_HotSpot_Coef_X -> SafeNvM
    connect MemAbstract_Stub_Safe.BsConst_PWM_boost_bypass_duty -> SafeNvM
    connect MemAbstract_Stub_Safe.BsConst_PCB_Temperature_Sensor_Conv -> SafeNvM
    delegation sw connector CComAbsMdl_stubs_pp_SR_TxBattery_Voltage_pp_SR_TxBattery_Voltage: inner-port=CComAbsMdl_stubs
    delegation sw connector CComAbsMdl_stubs_pp_SR_TxCurrentStateIC_pp_SR_TxCurrentStateIC: inner-port=CComAbsMdl_stubs.pp_SR_TxCurrentStateIC
    delegation sw connector CComAbsMdl_stubs_pp_SR_TxDebug1_Byte{0..7}_pp_SR_TxDebug1_Byte{0..7}: inner-port=CComAbsMdl_stubs.pp_SR_TxDebug1_Byte{0..7}
    delegation sw connector CComAbsMdl_stubs_pp_SR_TxDebug2_Byte{0..7}_pp_SR_TxDebug2_Byte{0..7}: inner-port=CComAbsMdl_stubs.pp_SR_TxDebug2_Byte{0..7}
    delegation sw connector CComAbsMdl_stubs_pp_SR_TxDebug3_Byte{0..7}_pp_SR_TxDebug3_Byte{0..7}: inner-port=CComAbsMdl_stubs.pp_SR_TxDebug3_Byte{0..7}
    delegation sw connector CComAbsMdl_stubs_pp_SR_TxDebug4_Byte{0..7}_pp_SR_TxDebug4_Byte{0..7}: inner-port=CComAbsMdl_stubs.pp_SR_TxDebug4_Byte{0..7}
    delegation sw connector CComAbsMdl_stubs_pp_SR_TxDebug5_Byte{0..7}_pp_SR_TxDebug5_Byte{0..7}: inner-port=CComAbsMdl_stubs.pp_SR_TxDebug5_Byte{0..7}
    delegation sw connector CComAbsMdl_stubs_pp_SR_TxDiag_Buffer_Tx_USDT_pp_SR_TxDiag_Buffer_Tx_USDT: inner-port=CComAbsMdl_stubs.pp_SR_TxDiag_Buffer_Tx_USDT
    delegation sw connector CComAbsMdl_stubs_pp_SR_TxDiag_Buffer_Tx_UUDT_pp_SR_TxDiag_Buffer_Tx_UUDT: inner-port=CComAbsMdl_stubs.pp_SR_TxDiag_Buffer_Tx_UUDT
    delegation sw connector CComAbsMdl_stubs_pp_SR_TxFV_Tx_pp_SR_TxFV_Tx: inner-port=CComAbsMdl_stubs.pp_SR_TxFV_Tx
    delegation sw connector CComAbsMdl_stubs_pp_SR_TxIllumination_PWM_pp_SR_TxIllumination_PWM: inner-port=CComAbsMdl_stubs.pp_SR_TxIllumination_PWM
    delegation sw connector CComAbsMdl_stubs_pp_SR_TxMAC_Tx_pp_SR_TxMAC_Tx: inner-port=CComAbsMdl_stubs.pp_SR_TxMAC_Tx
    delegation sw connector CComAbsMdl_stubs_pp_SR_TxOdometer_pp_SR_TxOdometer: inner-port=CComAbsMdl_stubs.pp_SR_TxOdometer
    delegation sw connector CComAbsMdl_stubs_pp_SR_TxPreviousStateIC_pp_SR_TxPreviousStateIC: inner-port=CComAbsMdl_stubs.pp_SR_TxPreviousStateIC
    delegation sw connector CComAbsMdl_stubs_pp_SR_TxSecureTxByte{0..3}_pp_SR_TxSecureTxByte{0..3}: inner-port=CComAbsMdl_stubs.pp_SR_TxSecureTxByte{0..3}
    delegation sw connector CComAbsMdl_stubs_pp_SR_TxUserData{1..5}_IC_pp_SR_TxUserData{1..5}_IC: inner-port=CComAbsMdl_stubs.pp_SR_TxUserData{1..5}_IC
    delegation sw connector CComAbsMdl_stubs_pp_SR_TxVehicleSpeedIC_pp_SR_TxVehicleSpeedIC: inner-port=CComAbsMdl_stubs.pp_SR_TxVehicleSpeedIC
    connect MemAbstract_Stub_Safe.BsConst_Temp_Threshold_Hysteresis_Derating -> SafeNvM
    connect MemAbstract_Stub_Safe.BsConst_Lookup_Curve_HotSpot_Coef_X -> SafeNvM
    connect MemAbstract_Stub_Safe.BsConst_Compensation_Line_Shift_b -> SafeNvM
    connect MemAbstract_Stub_Safe.BsConst_Temperature_Sensor_Conv -> SafeNvM
    connect MemAbstract_Stub_Safe.BsConst_BsConst_Illumination_ReservedByte -> SafeNvM
    connect MemAbstract_Stub_Safe.BsConst_Display_Illum_Max_Level_Safe -> SafeNvM
    connect MemAbstract_Stub_Safe.BsConst_Lookup_Curve_HotSpot_Coef_Y -> SafeNvM
    connect MemAbstract_Stub_Safe.BsConst_Derating_Backlight_Disable -> SafeNvM
    connect MemAbstract_Stub_Safe.BsConst_PWM_boost_bypass_duty -> SafeNvM
    connect MemAbstract_Stub_Safe.BsConst_PCB_Temperature_Sensor_Conv -> SafeNvM
    connect MemAbstract_Stub_Safe.BsConst_Compensation_Line_Slope_m -> SafeNvM
    connect MemAbstract_Stub_Safe.BsConst_Lookup_Curve_HotSpot_Coef_Y -> SafeNvM
    connect MemAbstract_Stub_Safe.BsConst_Derating_Backlight_Disable -> SafeNvM
    connect MemAbstract_Stub_Safe.BsConst_BsConst_Illumination_ReservedByte -> SafeNvM
    connect MemAbstract_Stub_Safe.BsConst_PWM_boost_bypass_duty -> SafeNvM
    connect MemAbstract_Stub_Safe.BsConst_Temperature_Sensor_Conv -> SafeNvM
    connect MemAbstract_Stub_Safe.BsConst_Lookup_Curve_HotSpot_Coef_X -> SafeNvM
    connect MemAbstract_Stub_Safe.BsConst_Display_Illum_Max_Level_Safe -> SafeNvM
    connect MemAbstract_Stub_Safe.BsConst_Temp_Threshold_Hysteresis_Derating -> SafeNvM
    connect MemAbstract_Stub_Safe.BsConst_Compensation_Line_Shift_b -> SafeNvM
    connect MemAbstract_Stub_Safe.BsConst_Compensation_Line_Slope_m -> SafeNvM
    connect MemAbstract_Stub_Safe.BsConst_PCB_Temperature_Sensor_Conv -> SafeNvM
    delegation sw connector rp_SR_RxAirbag_1_CComAbsMdl_stubs_rp_SR_RxAirbag_1: inner-port=CComAbsMdl_stubs
    delegation sw connector rp_SR_RxAirbag_2_CComAbsMdl_stubs_rp_SR_RxAirbag_1: inner-port=CComAbsMdl_stubs
    delegation sw connector rp_SR_RxAirbag_1_CComAbsMdl_stubs_rp_SR_RxAirbag_2: inner-port=CComAbsMdl_stubs
    connect MemAbstract_Stub_Safe.BsConst_Lookup_Curve_HotSpot_Coef_X -> SafeNvM
    connect MemAbstract_Stub_Safe.BsConst_PCB_Temperature_Sensor_Conv -> SafeNvM
    connect MemAbstract_Stub_Safe.BsConst_BsConst_Illumination_ReservedByte -> SafeNvM
    connect MemAbstract_Stub_Safe.BsConst_Display_Illum_Max_Level_Safe -> SafeNvM
    connect MemAbstract_Stub_Safe.BsConst_PWM_boost_bypass_duty -> SafeNvM
    connect MemAbstract_Stub_Safe.BsConst_Temperature_Sensor_Conv -> SafeNvM
    connect MemAbstract_Stub_Safe.BsConst_Lookup_Curve_HotSpot_Coef_Y -> SafeNvM
    connect MemAbstract_Stub_Safe.BsConst_Compensation_Line_Shift_b -> SafeNvM
    connect MemAbstract_Stub_Safe.BsConst_Compensation_Line_Slope_m -> SafeNvM
    connect MemAbstract_Stub_Safe.BsConst_Derating_Backlight_Disable -> SafeNvM
    connect MemAbstract_Stub_Safe.BsConst_Temp_Threshold_Hysteresis_Derating -> SafeNvM
    connect MemAbstract_Stub_Safe.BsConst_Lookup_Curve_HotSpot_Coef_Y -> SafeNvM
    connect MemAbstract_Stub_Safe.BsConst_Lookup_Curve_HotSpot_Coef_X -> SafeNvM
    connect MemAbstract_Stub_Safe.BsConst_BsConst_Illumination_ReservedByte -> SafeNvM
    connect MemAbstract_Stub_Safe.BsConst_Temperature_Sensor_Conv -> SafeNvM
    connect MemAbstract_Stub_Safe.BsConst_PCB_Temperature_Sensor_Conv -> SafeNvM
    connect MemAbstract_Stub_Safe.BsConst_Derating_Backlight_Disable -> SafeNvM
    connect MemAbstract_Stub_Safe.BsConst_Display_Illum_Max_Level_Safe -> SafeNvM
    connect MemAbstract_Stub_Safe.BsConst_Temp_Threshold_Hysteresis_Derating -> SafeNvM
    connect MemAbstract_Stub_Safe.BsConst_PWM_boost_bypass_duty -> SafeNvM
    connect MemAbstract_Stub_Safe.BsConst_Compensation_Line_Shift_b -> SafeNvM
    connect MemAbstract_Stub_Safe.BsConst_Compensation_Line_Slope_m -> SafeNvM
    connect NvBlockSwComponentType.BsRt_SpeedoGauge_Element -> MemAbstractStub.BsRt_SpeedoGauge_Element
    connect NvBlockSwComponentType.BsConst_Audio_Element -> MemAbstractStub.BsConst_Audio_Element
    connect NvBlockSwComponentType.BsConst_EngOffTimer_Element -> MemAbstractStub.BsConst_EngOffTimer_Element
    connect NvBlockSwComponentType.BsRt_OilGauge_Element -> MemAbstractStub.BsRt_OilGauge_Element
    connect NvBlockSwComponentType.BsShare_EcuPartNumber_Element -> MemAbstractStub.BsShare_EcuPartNumber_Element
    connect NvBlockSwComponentType.BsConst_PCB_Temperature_Sensor_Conv -> MemAbstractStub.BsConst_PCB_Temperature_Sensor_Conv
    connect NvBlockSwComponentType.BsConst_Compensation_Line_Slope_m_SafeCopy2 -> MemAbstractStub.BsConst_Compensation_Line_Slope_m_SafeCopy2
    connect NvBlockSwComponentType.BsConst_Temp_Threshold_Hysteresis_Derating_SafeCopy2 -> MemAbstractStub.BsConst_Temp_Threshold_Hysteresis_Derating_SafeCopy2
    connect NvBlockSwComponentType.BsConst_Compensation_Line_Shift_b -> MemAbstractStub.BsConst_Compensation_Line_Shift_b
    connect NvBlockSwComponentType.BsConst_Temperature_Sensor_Conv_SafeCopy2 -> MemAbstractStub.BsConst_Temperature_Sensor_Conv_SafeCopy2
    connect NvBlockSwComponentType.BsShare_VisteonPartNumber -> MemAbstractStub.BsShare_VisteonPartNumber
    connect NvBlockSwComponentType.BsConst_TempGauge_Element -> MemAbstractStub.BsConst_TempGauge_Element
    connect NvBlockSwComponentType.BsConst_Lookup_Curve_HotSpot_Coef_X -> MemAbstractStub.BsConst_Lookup_Curve_HotSpot_Coef_X
    connect NvBlockSwComponentType.BsConst_Temperature_Sensor_Conv_SafeCopy1 -> MemAbstractStub.BsConst_Temperature_Sensor_Conv_SafeCopy1
    connect NvBlockSwComponentType.BsReten_Personalization_Element -> MemAbstractStub.BsReten_Personalization_Element
    connect NvBlockSwComponentType.BsRt_RealTimeClock_Element -> MemAbstractStub.BsRt_RealTimeClock_Element
    connect NvBlockSwComponentType.BsConst_Derating_Backlight_Disable -> MemAbstractStub.BsConst_Derating_Backlight_Disable
    connect NvBlockSwComponentType.BsConst_Communication_Element -> MemAbstractStub.BsConst_Communication_Element
    connect NvBlockSwComponentType.BsRt_PowerGauge_Element -> MemAbstractStub.BsRt_PowerGauge_Element
    connect NvBlockSwComponentType.BsShare_VisMeet_EOLEntry_Element -> MemAbstractStub.BsShare_VisMeet_EOLEntry_Element
    connect NvBlockSwComponentType.BsConst_SpeedoGauge_Element -> MemAbstractStub.BsConst_SpeedoGauge_Element
    connect NvBlockSwComponentType.BsCys_Certicificate_Element -> MemAbstractStub.BsCys_Certicificate_Element
    connect NvBlockSwComponentType.BsReten_Tripcomputer_Element -> MemAbstractStub.BsReten_Tripcomputer_Element
    connect NvBlockSwComponentType.BsRt_FuelGauge_Element -> MemAbstractStub.BsRt_FuelGauge_Element
    connect NvBlockSwComponentType.BsConst_Lookup_Curve_HotSpot_Coef_Y -> MemAbstractStub.BsConst_Lookup_Curve_HotSpot_Coef_Y
    connect NvBlockSwComponentType.BsShare_SwUpdFotadecrypt_Element -> MemAbstractStub.BsShare_SwUpdFotadecrypt_Element
    connect NvBlockSwComponentType.BsRt_Personalization_Element -> MemAbstractStub.BsRt_Personalization_Element
    connect NvBlockSwComponentType.BsShare_VehicleConfig_Element -> MemAbstractStub.BsShare_VehicleConfig_Element
    connect NvBlockSwComponentType.BsConst_RealTimeClock_Element -> MemAbstractStub.BsConst_RealTimeClock_Element
    connect NvBlockSwComponentType.BsConst_TripComputer_Element -> MemAbstractStub.BsConst_TripComputer_Element
    connect NvBlockSwComponentType.BsRt_Odometer_Element -> MemAbstractStub.BsRt_Odometer_Element
    connect NvBlockSwComponentType.BsConst_Temp_Threshold_Hysteresis_Derating -> MemAbstractStub.BsConst_Temp_Threshold_Hysteresis_Derating
    connect NvBlockSwComponentType.BsShare_SMTManufacturingDate -> MemAbstractStub.BsShare_SMTManufacturingDate
    connect NvBlockSwComponentType.BsRt_TempGauge_Element -> MemAbstractStub.BsRt_TempGauge_Element
    connect NvBlockSwComponentType.BsReten_Power_Element -> MemAbstractStub.BsReten_Power_Element
    connect NvBlockSwComponentType.BsReten_Gauges_Element -> MemAbstractStub.BsReten_Gauges_Element
    connect NvBlockSwComponentType.BsShare_SMTPlantNumber -> MemAbstractStub.BsShare_SMTPlantNumber
    connect NvBlockSwComponentType.BsConst_PCB_Temperature_Sensor_Conv_SafeCopy1 -> MemAbstractStub.BsConst_PCB_Temperature_Sensor_Conv_SafeCopy1
    connect NvBlockSwComponentType.BsConst_Lookup_Curve_HotSpot_Coef_Y_SafeCopy2 -> MemAbstractStub.BsConst_Lookup_Curve_HotSpot_Coef_Y_SafeCopy2
    connect NvBlockSwComponentType.BsConst_BsConst_Illumination_ReservedByte_SafeCopy2 -> MemAbstractStub.BsConst_BsConst_Illumination_ReservedByte_SafeCopy2
    connect NvBlockSwComponentType.BsRt_Warning_Element -> MemAbstractStub.BsRt_Warning_Element
    connect NvBlockSwComponentType.BsReten_Warning_Element -> MemAbstractStub.BsReten_Warning_Element
    connect NvBlockSwComponentType.BsShare_AssemblyPlantNumber -> MemAbstractStub.BsShare_AssemblyPlantNumber
    connect NvBlockSwComponentType.BsConst_OilGauge_Element -> MemAbstractStub.BsConst_OilGauge_Element
    connect NvBlockSwComponentType.BsRt_Illumination_Element -> MemAbstractStub.BsRt_Illumination_Element
    connect NvBlockSwComponentType.RefCys_Certicificate_Element -> MemAbstractStub.RefCys_Certicificate_Element
    connect NvBlockSwComponentType.BsShare_VisMeet_Element -> MemAbstractStub.BsShare_VisMeet_Element
    connect NvBlockSwComponentType.BsConst_Derating_Backlight_Disable_SafeCopy1 -> MemAbstractStub.BsConst_Derating_Backlight_Disable_SafeCopy1
    connect NvBlockSwComponentType.BsShare_ProductSerialNumber -> MemAbstractStub.BsShare_ProductSerialNumber
    connect NvBlockSwComponentType.BsConst_ServiceReminder_Element -> MemAbstractStub.BsConst_ServiceReminder_Element
    connect NvBlockSwComponentType.BsShare_AssemblyManufacturingDate -> MemAbstractStub.BsShare_AssemblyManufacturingDate
    connect NvBlockSwComponentType.BsConst_Display_Illum_Max_Level -> MemAbstractStub.BsConst_Display_Illum_Max_Level
    connect NvBlockSwComponentType.BsRt_TripComputer_Element -> MemAbstractStub.BsRt_TripComputer_Element
    connect NvBlockSwComponentType.BsShare_HWModification -> MemAbstractStub.BsShare_HWModification
    connect NvBlockSwComponentType.BsConst_FuelGauge_Element -> MemAbstractStub.BsConst_FuelGauge_Element
    connect NvBlockSwComponentType.BsConst_TachoGauge_Element -> MemAbstractStub.BsConst_TachoGauge_Element
    connect NvBlockSwComponentType.BsConst_PWM_boost_bypass_duty -> MemAbstractStub.BsConst_PWM_boost_bypass_duty
    connect NvBlockSwComponentType.BsShare_SwUpdFotaFinPrint_Element -> MemAbstractStub.BsShare_SwUpdFotaFinPrint_Element
    connect NvBlockSwComponentType.BsConst_PWM_boost_bypass_duty_SafeCopy2 -> MemAbstractStub.BsConst_PWM_boost_bypass_duty_SafeCopy2
    connect NvBlockSwComponentType.BsConst_Temperature_Sensor_Conv -> MemAbstractStub.BsConst_Temperature_Sensor_Conv
    connect NvBlockSwComponentType.BsConst_Lookup_Curve_HotSpot_Coef_Y_SafeCopy1 -> MemAbstractStub.BsConst_Lookup_Curve_HotSpot_Coef_Y_SafeCopy1
    connect NvBlockSwComponentType.BsReten_Odometer_Element -> MemAbstractStub.BsReten_Odometer_Element
    connect NvBlockSwComponentType.BsConst_Compensation_Line_Shift_b_SafeCopy1 -> MemAbstractStub.BsConst_Compensation_Line_Shift_b_SafeCopy1
    connect NvBlockSwComponentType.BsReten_RealTimeClock_Element -> MemAbstractStub.BsReten_RealTimeClock_Element
    connect NvBlockSwComponentType.BsConst_Derating_Backlight_Disable_SafeCopy2 -> MemAbstractStub.BsConst_Derating_Backlight_Disable_SafeCopy2
    connect NvBlockSwComponentType.BsConst_Compensation_Line_Slope_m_SafeCopy1 -> MemAbstractStub.BsConst_Compensation_Line_Slope_m_SafeCopy1
    connect NvBlockSwComponentType.BsReten_Communication_Element -> MemAbstractStub.BsReten_Communication_Element
    connect NvBlockSwComponentType.BsConst_Power_Element -> MemAbstractStub.BsConst_Power_Element
    connect NvBlockSwComponentType.BsConst_Compensation_Line_Slope_m -> MemAbstractStub.BsConst_Compensation_Line_Slope_m
    connect NvBlockSwComponentType.BsShare_SwUpdFotaStatus_Element -> MemAbstractStub.BsShare_SwUpdFotaStatus_Element
    connect NvBlockSwComponentType.BsDiag_ErrorRecord_Element -> MemAbstractStub.BsDiag_ErrorRecord_Element
    connect NvBlockSwComponentType.BsConst_Temp_Threshold_Hysteresis_Derating_SafeCopy1 -> MemAbstractStub.BsConst_Temp_Threshold_Hysteresis_Derating_SafeCopy1
    connect NvBlockSwComponentType.RefCys_Certicificate1_Element -> MemAbstractStub.RefCys_Certicificate1_Element
    connect NvBlockSwComponentType.BsDiag_Dtc_Element -> MemAbstractStub.BsDiag_Dtc_Element
    connect NvBlockSwComponentType.BsConst_Compensation_Line_Shift_b_SafeCopy2 -> MemAbstractStub.BsConst_Compensation_Line_Shift_b_SafeCopy2
    connect NvBlockSwComponentType.BsConst_Display_Illum_Max_Level_SafeCopy2 -> MemAbstractStub.BsConst_Display_Illum_Max_Level_SafeCopy2
    connect NvBlockSwComponentType.BsRt_CusDlt_Element -> MemAbstractStub.BsRt_CusDlt_Element
    connect NvBlockSwComponentType.BsReten_Audio_Element -> MemAbstractStub.BsReten_Audio_Element
    connect NvBlockSwComponentType.BsRt_TachoGauge_Element -> MemAbstractStub.BsRt_TachoGauge_Element
    connect NvBlockSwComponentType.BsReten_Illumination_Element -> MemAbstractStub.BsReten_Illumination_Element
    connect NvBlockSwComponentType.BsConst_BsConst_Illumination_ReservedByte_SafeCopy1 -> MemAbstractStub.BsConst_BsConst_Illumination_ReservedByte_SafeCopy1
    connect NvBlockSwComponentType.BsConst_Lookup_Curve_HotSpot_Coef_X_SafeCopy1 -> MemAbstractStub.BsConst_Lookup_Curve_HotSpot_Coef_X_SafeCopy1
    connect NvBlockSwComponentType.BsConst_BsConst_Illumination_ReservedByte -> MemAbstractStub.BsConst_BsConst_Illumination_ReservedByte
    connect NvBlockSwComponentType.BsConst_Warning_Element -> MemAbstractStub.BsConst_Warning_Element
    connect NvBlockSwComponentType.BsShare_SwUpdFotaMode_Element -> MemAbstractStub.BsShare_SwUpdFotaMode_Element
    connect NvBlockSwComponentType.BsReten_Display_Element -> MemAbstractStub.BsReten_Display_Element
    connect NvBlockSwComponentType.BsConst_PCB_Temperature_Sensor_Conv_SafeCopy2 -> MemAbstractStub.BsConst_PCB_Temperature_Sensor_Conv_SafeCopy2
    connect NvBlockSwComponentType.BsShare_SwUpdReflash_Element -> MemAbstractStub.BsShare_SwUpdReflash_Element
    connect NvBlockSwComponentType.BsShare_VisteonPCBPartNumber -> MemAbstractStub.BsShare_VisteonPCBPartNumber
    connect NvBlockSwComponentType.BsConst_Lookup_Curve_HotSpot_Coef_X_SafeCopy2 -> MemAbstractStub.BsConst_Lookup_Curve_HotSpot_Coef_X_SafeCopy2
    connect NvBlockSwComponentType.BsConst_Display_Illum_Max_Level_SafeCopy1 -> MemAbstractStub.BsConst_Display_Illum_Max_Level_SafeCopy1
    connect NvBlockSwComponentType.BsConst_PWM_boost_bypass_duty_SafeCopy1 -> MemAbstractStub.BsConst_PWM_boost_bypass_duty_SafeCopy1
    connect NvBlockSwComponentType.BsShare_PCBSerialNumber -> MemAbstractStub.BsShare_PCBSerialNumber
    connect NvBlockSwComponentType.BsConst_PowerGauge_Element -> MemAbstractStub.BsConst_PowerGauge_Element
    delegation sw connector TrustecSWC_PP_TX_SG_COM_HSSG_COM_HS_PP_TX_SG_COM_HSSG_COM_HS: inner-port=TrustecSWC.PP_TX_SG_COM_HS
    delegate TrustecSWC <-> outer port PP_TX_SG_COM_HSSG_COM_HS
    delegate CComAbsMdl_stubs <-> outer port rp_SR_RxAmbient_Light_level
    delegation sw connector CComAbsMdl_stubs_rp_SR_RxCurrentStateIC_rp_SR_RxCurrentStateIC: inner-port=CComAbsMdl_stubs.rp_SR_RxCurrentStateIC
    delegate CComAbsMdl_stubs <-> outer port rp_SR_RxDayNightMode
    delegate CComAbsMdl_stubs <-> outer port rp_SR_RxGear
    delegate CComAbsMdl_stubs <-> outer port rp_SR_RxGearMode
    delegate CComAbsMdl_stubs <-> outer port rp_SR_RxGearRecommendation
    delegate CComAbsMdl_stubs <-> outer port rp_SR_RxGearStatus
    delegate CComAbsMdl_stubs <-> outer port rp_SR_RxIllumination_level
    delegate CComAbsMdl_stubs <-> outer port rp_SR_RxPowerMode
    delegate CComAbsMdl_stubs <-> outer port rp_SR_RxTransportMode
    delegate CComAbsMdl_stubs <-> outer port rp_SR_RxWarning
    delegate CComAbsMdl_stubs <-> outer port pp_SR_TxDebug1_Byte{0..7}
    delegate CComAbsMdl_stubs <-> outer port pp_SR_TxDebug2_Byte{0..7}
    delegate CComAbsMdl_stubs <-> outer port pp_SR_TxDebug3_Byte{0..7}
    delegate CComAbsMdl_stubs <-> outer port pp_SR_TxDebug4_Byte{0..7}
    delegate CComAbsMdl_stubs <-> outer port pp_SR_TxDebug5_Byte{0..7}
    delegate CComAbsMdl_stubs <-> outer port pp_SR_TxFV_Tx
    delegate CComAbsMdl_stubs <-> outer port pp_SR_TxIllumination_PWM
    delegate CComAbsMdl_stubs <-> outer port pp_SR_TxMAC_Tx
    delegate CComAbsMdl_stubs <-> outer port pp_SR_TxOdometer
    delegate CComAbsMdl_stubs <-> outer port pp_SR_TxSecureTxByte{0..3}
    delegate CComAbsMdl_stubs <-> outer port pp_SR_TxVehicleSpeedIC
    connect MemAbstract_Stub_Safe.BsConst_Lookup_Curve_HotSpot_Coef_Y -> SafeNvM
    connect MemAbstract_Stub_Safe.BsConst_Compensation_Line_Shift_b -> SafeNvM
    connect MemAbstract_Stub_Safe.BsConst_Temp_Threshold_Hysteresis_Derating -> SafeNvM
    connect MemAbstract_Stub_Safe.BsConst_BsConst_Illumination_ReservedByte -> SafeNvM
    connect MemAbstract_Stub_Safe.BsConst_PCB_Temperature_Sensor_Conv -> SafeNvM
    connect MemAbstract_Stub_Safe.BsConst_Display_Illum_Max_Level_Safe -> SafeNvM
    connect MemAbstract_Stub_Safe.BsConst_Derating_Backlight_Disable -> SafeNvM
    connect MemAbstract_Stub_Safe.BsConst_Compensation_Line_Slope_m -> SafeNvM
    connect MemAbstract_Stub_Safe.BsConst_PWM_boost_bypass_duty -> SafeNvM
    connect MemAbstract_Stub_Safe.BsConst_Temperature_Sensor_Conv -> SafeNvM
    connect MemAbstract_Stub_Safe.BsConst_Lookup_Curve_HotSpot_Coef_X -> SafeNvM
    connect MemAbstract_Stub_Safe.BsConst_PWM_boost_bypass_duty -> SafeNvM
    connect MemAbstract_Stub_Safe.BsConst_Derating_Backlight_Disable -> SafeNvM
    connect MemAbstract_Stub_Safe.BsConst_Compensation_Line_Shift_b -> SafeNvM
    connect MemAbstract_Stub_Safe.BsConst_Lookup_Curve_HotSpot_Coef_Y -> SafeNvM
    connect MemAbstract_Stub_Safe.BsConst_PCB_Temperature_Sensor_Conv -> SafeNvM
    connect MemAbstract_Stub_Safe.BsConst_BsConst_Illumination_ReservedByte -> SafeNvM
    connect MemAbstract_Stub_Safe.BsConst_Lookup_Curve_HotSpot_Coef_X -> SafeNvM
    connect MemAbstract_Stub_Safe.BsConst_Display_Illum_Max_Level_Safe -> SafeNvM
    connect MemAbstract_Stub_Safe.BsConst_Temperature_Sensor_Conv -> SafeNvM
    connect MemAbstract_Stub_Safe.BsConst_Compensation_Line_Slope_m -> SafeNvM
    connect MemAbstract_Stub_Safe.BsConst_Temp_Threshold_Hysteresis_Derating -> SafeNvM
    connect MemAbstract_Stub_Safe.BsConst_Lookup_Curve_HotSpot_Coef_Y -> SafeNvM
    connect MemAbstract_Stub_Safe.BsConst_BsConst_Illumination_ReservedByte -> SafeNvM
    connect MemAbstract_Stub_Safe.BsConst_PCB_Temperature_Sensor_Conv -> SafeNvM
    connect MemAbstract_Stub_Safe.BsConst_Temperature_Sensor_Conv -> SafeNvM
    connect MemAbstract_Stub_Safe.BsConst_Lookup_Curve_HotSpot_Coef_X -> SafeNvM
    connect MemAbstract_Stub_Safe.BsConst_Derating_Backlight_Disable -> SafeNvM
    connect MemAbstract_Stub_Safe.BsConst_PWM_boost_bypass_duty -> SafeNvM
    connect MemAbstract_Stub_Safe.BsConst_Compensation_Line_Slope_m -> SafeNvM
    connect MemAbstract_Stub_Safe.BsConst_Compensation_Line_Shift_b -> SafeNvM
    connect MemAbstract_Stub_Safe.BsConst_Temp_Threshold_Hysteresis_Derating -> SafeNvM
    connect MemAbstract_Stub_Safe.BsConst_Display_Illum_Max_Level_Safe -> SafeNvM
    connect MemAbstract_Stub_Safe.BsConst_Lookup_Curve_HotSpot_Coef_Y -> SafeNvM
    connect MemAbstract_Stub_Safe.BsConst_BsConst_Illumination_ReservedByte -> SafeNvM
    connect MemAbstract_Stub_Safe.BsConst_PCB_Temperature_Sensor_Conv -> SafeNvM
    connect MemAbstract_Stub_Safe.BsConst_Temperature_Sensor_Conv -> SafeNvM
    connect MemAbstract_Stub_Safe.BsConst_Lookup_Curve_HotSpot_Coef_X -> SafeNvM
    connect MemAbstract_Stub_Safe.BsConst_Derating_Backlight_Disable -> SafeNvM
    connect MemAbstract_Stub_Safe.BsConst_PWM_boost_bypass_duty -> SafeNvM
    connect MemAbstract_Stub_Safe.BsConst_Compensation_Line_Slope_m -> SafeNvM
    connect MemAbstract_Stub_Safe.BsConst_Compensation_Line_Shift_b -> SafeNvM
    connect MemAbstract_Stub_Safe.BsConst_Temp_Threshold_Hysteresis_Derating -> SafeNvM
    connect MemAbstract_Stub_Safe.BsConst_Display_Illum_Max_Level_Safe -> SafeNvM
    connect MemAbstract_Stub_Safe.BsConst_Lookup_Curve_HotSpot_Coef_X -> SafeNvM
    connect MemAbstract_Stub_Safe.BsConst_Display_Illum_Max_Level_Safe -> SafeNvM
    connect MemAbstract_Stub_Safe.BsConst_PCB_Temperature_Sensor_Conv -> SafeNvM
    connect MemAbstract_Stub_Safe.BsConst_BsConst_Illumination_ReservedByte -> SafeNvM
    connect MemAbstract_Stub_Safe.BsConst_Compensation_Line_Slope_m -> SafeNvM
    connect MemAbstract_Stub_Safe.BsConst_Lookup_Curve_HotSpot_Coef_Y -> SafeNvM
    connect MemAbstract_Stub_Safe.BsConst_PWM_boost_bypass_duty -> SafeNvM
    connect MemAbstract_Stub_Safe.BsConst_Temperature_Sensor_Conv -> SafeNvM
    connect MemAbstract_Stub_Safe.BsConst_Compensation_Line_Shift_b -> SafeNvM
    connect MemAbstract_Stub_Safe.BsConst_Derating_Backlight_Disable -> SafeNvM
    connect MemAbstract_Stub_Safe.BsConst_Temp_Threshold_Hysteresis_Derating -> SafeNvM
    connect MemAbstract_Stub_Safe.BsConst_Temperature_Sensor_Conv -> SafeNvM
    connect MemAbstract_Stub_Safe.BsConst_PCB_Temperature_Sensor_Conv -> SafeNvM
    connect MemAbstract_Stub_Safe.BsConst_Compensation_Line_Shift_b -> SafeNvM
    connect MemAbstract_Stub_Safe.BsConst_Compensation_Line_Slope_m -> SafeNvM
    connect MemAbstract_Stub_Safe.BsConst_PWM_boost_bypass_duty -> SafeNvM
    connect MemAbstract_Stub_Safe.BsConst_Derating_Backlight_Disable -> SafeNvM
    connect MemAbstract_Stub_Safe.BsConst_Lookup_Curve_HotSpot_Coef_Y -> SafeNvM
    connect MemAbstract_Stub_Safe.BsConst_BsConst_Illumination_ReservedByte -> SafeNvM
    connect MemAbstract_Stub_Safe.BsConst_Temp_Threshold_Hysteresis_Derating -> SafeNvM
    connect MemAbstract_Stub_Safe.BsConst_Lookup_Curve_HotSpot_Coef_X -> SafeNvM
    connect MemAbstract_Stub_Safe.BsConst_Display_Illum_Max_Level_Safe -> SafeNvM
    delegation sw connector rp_SR_RxEngineSpeed_CComAbsMdl_stubs_rp_SR_RxEngineSpeed: inner-port=CComAbsMdl_stubs.rp_SR_RxEngineSpeed
    delegation sw connector rp_SR_RxTurn_Indicator_Control_CComAbsMdl_stubs_rp_SR_RxTurn_Indicator_Control: inner-port=CComAbsMdl_stubs.rp_SR_RxTurn_Indicator_Control
    connect MemAbstract_Stub_Safe.BsConst_Compensation_Line_Shift_b -> SafeNvM
    connect MemAbstract_Stub_Safe.BsConst_Display_Illum_Max_Level_Safe -> SafeNvM
    connect MemAbstract_Stub_Safe.BsConst_Derating_Backlight_Disable -> SafeNvM
    connect MemAbstract_Stub_Safe.BsConst_PCB_Temperature_Sensor_Conv -> SafeNvM
    connect MemAbstract_Stub_Safe.BsConst_Temperature_Sensor_Conv -> SafeNvM
    connect MemAbstract_Stub_Safe.BsConst_Lookup_Curve_HotSpot_Coef_Y -> SafeNvM
    connect MemAbstract_Stub_Safe.BsConst_Lookup_Curve_HotSpot_Coef_X -> SafeNvM
    connect MemAbstract_Stub_Safe.BsConst_BsConst_Illumination_ReservedByte -> SafeNvM
    connect MemAbstract_Stub_Safe.BsConst_PWM_boost_bypass_duty -> SafeNvM
    connect MemAbstract_Stub_Safe.BsConst_Compensation_Line_Slope_m -> SafeNvM
    connect MemAbstract_Stub_Safe.BsConst_Temp_Threshold_Hysteresis_Derating -> SafeNvM
    delegate CComAbsMdl_stubs.rp_SR_RxEngineSpeed_1 <-> outer port rp_SR_RxEngineSpeed
    delegate CComAbsMdl_stubs.rp_SR_RxTurn_Indicator_Control_1 <-> outer port rp_SR_RxTurn_Indicator_Control
    connect MemAbstract_Stub_Safe.BsConst_PCB_Temperature_Sensor_Conv -> SafeNvM
    connect MemAbstract_Stub_Safe.BsConst_PWM_boost_bypass_duty -> SafeNvM
    connect MemAbstract_Stub_Safe.BsConst_Temp_Threshold_Hysteresis_Derating -> SafeNvM
    connect MemAbstract_Stub_Safe.BsConst_Derating_Backlight_Disable -> SafeNvM
    connect MemAbstract_Stub_Safe.BsConst_Temperature_Sensor_Conv -> SafeNvM
    connect MemAbstract_Stub_Safe.BsConst_Lookup_Curve_HotSpot_Coef_Y -> SafeNvM
    connect MemAbstract_Stub_Safe.BsConst_Compensation_Line_Slope_m -> SafeNvM
    connect MemAbstract_Stub_Safe.BsConst_Lookup_Curve_HotSpot_Coef_X -> SafeNvM
    connect MemAbstract_Stub_Safe.BsConst_Display_Illum_Max_Level_Safe -> SafeNvM
    connect MemAbstract_Stub_Safe.BsConst_Compensation_Line_Shift_b -> SafeNvM
    connect MemAbstract_Stub_Safe.BsConst_BsConst_Illumination_ReservedByte -> SafeNvM
    connect MemAbstract_Stub_Safe.BsConst_Compensation_Line_Shift_b -> SafeNvM
    connect MemAbstract_Stub_Safe.BsConst_Display_Illum_Max_Level_Safe -> SafeNvM
    connect MemAbstract_Stub_Safe.BsConst_PCB_Temperature_Sensor_Conv -> SafeNvM
    connect MemAbstract_Stub_Safe.BsConst_Temp_Threshold_Hysteresis_Derating -> SafeNvM
    connect MemAbstract_Stub_Safe.BsConst_Compensation_Line_Slope_m -> SafeNvM
    connect MemAbstract_Stub_Safe.BsConst_Temperature_Sensor_Conv -> SafeNvM
    connect MemAbstract_Stub_Safe.BsConst_PWM_boost_bypass_duty -> SafeNvM
    connect MemAbstract_Stub_Safe.BsConst_Derating_Backlight_Disable -> SafeNvM
    connect MemAbstract_Stub_Safe.BsConst_Lookup_Curve_HotSpot_Coef_X -> SafeNvM
    connect MemAbstract_Stub_Safe.BsConst_BsConst_Illumination_ReservedByte -> SafeNvM
    connect MemAbstract_Stub_Safe.BsConst_Lookup_Curve_HotSpot_Coef_Y -> SafeNvM
    connect MemAbstract_Stub_Safe.BsConst_Temp_Threshold_Hysteresis_Derating -> SafeNvM
    connect MemAbstract_Stub_Safe.BsConst_Lookup_Curve_HotSpot_Coef_X -> SafeNvM
    connect MemAbstract_Stub_Safe.BsConst_Compensation_Line_Slope_m -> SafeNvM
    connect MemAbstract_Stub_Safe.BsConst_PWM_boost_bypass_duty -> SafeNvM
    connect MemAbstract_Stub_Safe.BsConst_Temperature_Sensor_Conv -> SafeNvM
    connect MemAbstract_Stub_Safe.BsConst_BsConst_Illumination_ReservedByte -> SafeNvM
    connect MemAbstract_Stub_Safe.BsConst_Lookup_Curve_HotSpot_Coef_Y -> SafeNvM
    connect MemAbstract_Stub_Safe.BsConst_Compensation_Line_Shift_b -> SafeNvM
    connect MemAbstract_Stub_Safe.BsConst_Display_Illum_Max_Level_Safe -> SafeNvM
    connect MemAbstract_Stub_Safe.BsConst_PCB_Temperature_Sensor_Conv -> SafeNvM
    connect MemAbstract_Stub_Safe.BsConst_Derating_Backlight_Disable -> SafeNvM
    connect MemAbstract_Stub_Safe.BsConst_Derating_Backlight_Disable -> SafeNvM.BsConst_Derating_Backlight_Disable
    connect MemAbstract_Stub_Safe.BsConst_Temperature_Sensor_Conv -> SafeNvM.BsConst_Temperature_Sensor_Conv
    connect MemAbstract_Stub_Safe.BsConst_Lookup_Curve_HotSpot_Coef_X -> SafeNvM.BsConst_Lookup_Curve_HotSpot_Coef_X
    connect MemAbstract_Stub_Safe.BsConst_Display_Illum_Max_Level_Safe -> SafeNvM.BsConst_Display_Illum_Max_Level_Safe
    connect MemAbstract_Stub_Safe.BsConst_Temp_Threshold_Hysteresis_Derating -> SafeNvM.BsConst_Temp_Threshold_Hysteresis_Derating
    connect MemAbstract_Stub_Safe.BsConst_PWM_boost_bypass_duty -> SafeNvM.BsConst_PWM_boost_bypass_duty
    connect MemAbstract_Stub_Safe.BsConst_BsConst_Illumination_ReservedByte -> SafeNvM.BsConst_BsConst_Illumination_ReservedByte
    connect MemAbstract_Stub_Safe.BsConst_Lookup_Curve_HotSpot_Coef_Y -> SafeNvM.BsConst_Lookup_Curve_HotSpot_Coef_Y
    connect MemAbstract_Stub_Safe.BsConst_Compensation_Line_Shift_b -> SafeNvM.BsConst_Compensation_Line_Shift_b
    connect MemAbstract_Stub_Safe.BsConst_PCB_Temperature_Sensor_Conv -> SafeNvM.BsConst_PCB_Temperature_Sensor_Conv
    connect MemAbstract_Stub_Safe.BsConst_Compensation_Line_Slope_m -> SafeNvM.BsConst_Compensation_Line_Slope_m
package /EndToEndProtections
  end to end protection set EndToEndProtectionSet
